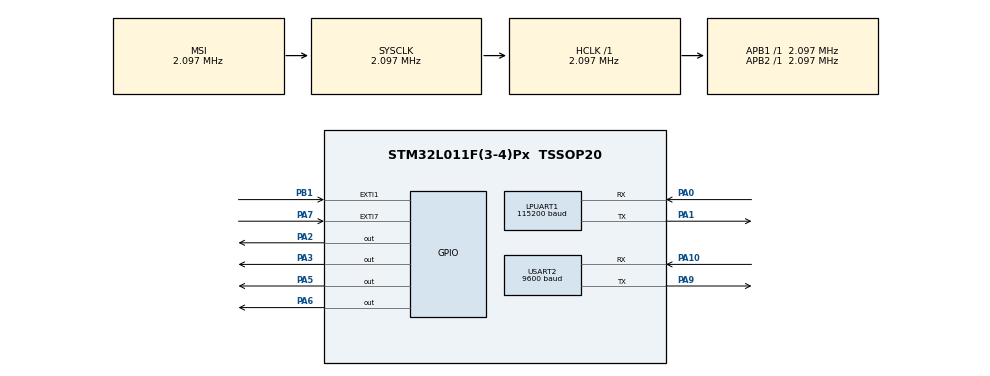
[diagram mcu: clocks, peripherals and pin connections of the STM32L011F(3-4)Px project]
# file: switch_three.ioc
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Dma.LPUART1_RX.0.Direction=DMA_PERIPH_TO_MEMORY
Dma.LPUART1_RX.0.Instance=DMA1_Channel3
Dma.LPUART1_RX.0.MemDataAlignment=DMA_MDATAALIGN_BYTE
Dma.LPUART1_RX.0.MemInc=DMA_MINC_ENABLE
Dma.LPUART1_RX.0.Mode=DMA_NORMAL
Dma.LPUART1_RX.0.PeriphDataAlignment=DMA_PDATAALIGN_BYTE
Dma.LPUART1_RX.0.PeriphInc=DMA_PINC_DISABLE
Dma.LPUART1_RX.0.Priority=DMA_PRIORITY_LOW
Dma.Request0=LPUART1_RX
Dma.Request1=USART2_RX
Dma.USART2_RX.1.Direction=DMA_PERIPH_TO_MEMORY
Dma.USART2_RX.1.Instance=DMA1_Channel5
Dma.USART2_RX.1.MemDataAlignment=DMA_MDATAALIGN_BYTE
Dma.USART2_RX.1.MemInc=DMA_MINC_ENABLE
Dma.USART2_RX.1.Mode=DMA_NORMAL
Dma.USART2_RX.1.PeriphDataAlignment=DMA_PDATAALIGN_BYTE
Dma.USART2_RX.1.PeriphInc=DMA_PINC_DISABLE
Dma.USART2_RX.1.Priority=DMA_PRIORITY_LOW
LPUART1.BaudRate=115200
LPUART1.MSBFirstParam=UART_ADVFEATURE_MSBFIRST_ENABLE
Mcu.Family=STM32L0
Mcu.Name=STM32L011F(3-4)Px
Mcu.Package=TSSOP20
NVIC.AES_RNG_LPUART1_IRQn=true\:0\:0\:false\:false\:true\:true
NVIC.DMA1_Channel2_3_IRQn=true\:0\:0\:false\:false\:true\:false
NVIC.DMA1_Channel4_5_6_7_IRQn=true\:0\:0\:false\:false\:true\:false
NVIC.EXTI0_1_IRQn=true\:0\:0\:false\:false\:true\:true
NVIC.EXTI4_15_IRQn=true\:0\:0\:false\:false\:true\:true
NVIC.USART2_IRQn=true\:0\:0\:false\:false\:true\:true
PA0-CK_IN.Mode=Asynchronous
PA0-CK_IN.Signal=LPUART1_RX
PA1.Mode=Asynchronous
PA1.Signal=LPUART1_TX
PA10.Mode=Asynchronous
PA10.Signal=USART2_RX
PA13.Mode=Serial_Wire
PA13.Signal=SYS_SWDIO
PA14.Mode=Serial_Wire
PA14.Signal=SYS_SWCLK
PA2.Signal=GPIO_Output
PA3.Signal=GPIO_Output
PA5.Signal=GPIO_Output
PA6.Signal=GPIO_Output
PA7.Signal=GPXTI7
PA9.Mode=Asynchronous
PA9.Signal=USART2_TX
PB1.Signal=GPXTI1
PC14-OSC32_IN.Mode=LSE-External-Oscillator
PC14-OSC32_IN.Signal=RCC_OSC32_IN
PC15-OSC32_OUT.Mode=LSE-External-Oscillator
PC15-OSC32_OUT.Signal=RCC_OSC32_OUT
ProjectManager.HeapSize=0x200
ProjectManager.StackSize=0x400
ProjectManager.TargetToolchain=MDK-ARM V5
RCC.AHBFreq_Value=2097000
RCC.APB1Freq_Value=2097000
RCC.APB1TimFreq_Value=2097000
RCC.APB2Freq_Value=2097000
RCC.APB2TimFreq_Value=2097000
RCC.HSE_VALUE=8000000
RCC.HSI16_VALUE=16000000
RCC.HSI_VALUE=16000000
RCC.MSI_VALUE=2097000
RCC.SYSCLKFreq_VALUE=2097000
RCC.VCOOutputFreq_Value=48000000
USART2.BaudRate=9600
USART2.MSBFirstParam=ADVFEATURE_MSBFIRST_ENABLE
USART2.VirtualMode-Asynchronous=VM_ASYNC
board=custom

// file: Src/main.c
#include "includes.h"

UART_HandleTypeDef hlpuart1;
UART_HandleTypeDef huart2;
DMA_HandleTypeDef hdma_lpuart1_rx;
DMA_HandleTypeDef hdma_lpuart1_tx;
DMA_HandleTypeDef hdma_usart2_rx;
DMA_HandleTypeDef hdma_usart2_tx;

/* USER CODE BEGIN PV */
/* Private variables ---------------------------------------------------------*/

/* USER CODE END PV */

/* Size of Trasmission buffer */
#define TXBUFFERSIZE                      (COUNTOF(aTxBuffer) - 1)
/* Size of Reception buffer */
#define RXBUFFERSIZE                      TXBUFFERSIZE
#define COUNTOF(__BUFFER__)   (sizeof(__BUFFER__) / sizeof(*(__BUFFER__)))

/* uart2 receive  parameter*/
uint8_t rx_buffer[100] = {0};
uint8_t tx_buffer[100] = {0};
uint16_t rx_len = 0;
/* UART handler declaration */
__IO ITStatus UartReady = RESET;

uint8_t aTxBuffer[] = " ****UART_TwoBoards_ComIT****  ****UART_TwoBoards_ComIT****  ****UART_TwoBoards_ComIT**** ";

/* Buffer used for reception */
uint8_t aRxBuffer[RXBUFFERSIZE];

/* is done recevice */
uint8_t recv_end_flag = 0;

int main(void)
{
	/* Reset of all peripherals, Initializes the Flash interface and the Systick. */
	HAL_Init();

	/* Configure the system clock */
	SystemClock_Config();

	/* Initialize all configured peripherals */
	MX_GPIO_Init();
	//MX_DMA_Init();
	MX_LPUART1_UART_Init();
	MX_USART2_UART_Init();

	while (1)
	{
//wifi串口数据解析
//继电器控制
//485数据解析
	//	HAL_UART_Transmit_DMA(&huart2, "test", 5); //
	//	rx_len = 0;
	//	recv_end_flag = 0;
	//	HAL_UART_Receive_DMA(&huart2, rx_buffer, BUFFER_SIZE);
		//灯
		 HAL_GPIO_TogglePin(GPIOA, GPIO_PIN_4);
		//继电器控制
		HAL_GPIO_TogglePin(GPIOA, GPIO_PIN_3);
    /* Insert delay 100 ms */
    HAL_Delay(3000);

	}

}

void SystemClock_Config(void)
{

	RCC_OscInitTypeDef RCC_OscInitStruct={0};
	RCC_ClkInitTypeDef RCC_ClkInitStruct={0};

	/**Configure the main internal regulator output voltage
	*/
	__HAL_PWR_VOLTAGESCALING_CONFIG(PWR_REGULATOR_VOLTAGE_SCALE1);

	/**Initializes the CPU, AHB and APB busses clocks
	*/
	RCC_OscInitStruct.OscillatorType = RCC_OSCILLATORTYPE_MSI;
	RCC_OscInitStruct.MSIState = RCC_MSI_ON;
	RCC_OscInitStruct.MSICalibrationValue = 0;
	RCC_OscInitStruct.MSIClockRange = RCC_MSIRANGE_5;
	RCC_OscInitStruct.PLL.PLLState = RCC_PLL_NONE;

	if (HAL_RCC_OscConfig(&RCC_OscInitStruct) != HAL_OK)
	{
		_Error_Handler(__FILE__, __LINE__);
	}

	/**Initializes the CPU, AHB and APB busses clocks
	*/
	RCC_ClkInitStruct.ClockType = RCC_CLOCKTYPE_HCLK | RCC_CLOCKTYPE_SYSCLK
								  | RCC_CLOCKTYPE_PCLK1 | RCC_CLOCKTYPE_PCLK2;
	RCC_ClkInitStruct.SYSCLKSource = RCC_SYSCLKSOURCE_MSI;
	RCC_ClkInitStruct.AHBCLKDivider = RCC_SYSCLK_DIV1;
	RCC_ClkInitStruct.APB1CLKDivider = RCC_HCLK_DIV1;
	RCC_ClkInitStruct.APB2CLKDivider = RCC_HCLK_DIV1;

	if (HAL_RCC_ClockConfig(&RCC_ClkInitStruct, FLASH_LATENCY_0) != HAL_OK)
	{
		_Error_Handler(__FILE__, __LINE__);
	}

	/**Configure the Systick interrupt time
	*/
	HAL_SYSTICK_Config(HAL_RCC_GetHCLKFreq() / 1000);

	/**Configure the Systick
	*/
	HAL_SYSTICK_CLKSourceConfig(SYSTICK_CLKSOURCE_HCLK);

	/* SysTick_IRQn interrupt configuration */
	HAL_NVIC_SetPriority(SysTick_IRQn, 0, 0);

}

/* LPUART1 init function */
void MX_LPUART1_UART_Init(void)
{

	hlpuart1.Instance = LPUART1;
	hlpuart1.Init.BaudRate = 115200;
	hlpuart1.Init.WordLength = UART_WORDLENGTH_8B;
	hlpuart1.Init.StopBits = UART_STOPBITS_1;
	hlpuart1.Init.Parity = UART_PARITY_NONE;
	hlpuart1.Init.Mode = UART_MODE_TX_RX;
	hlpuart1.Init.HwFlowCtl = UART_HWCONTROL_NONE;
	//hlpuart1.Init.OneBitSampling = UART_ONE_BIT_SAMPLE_DISABLE;
	//hlpuart1.AdvancedInit.AdvFeatureInit = UART_ADVFEATURE_MSBFIRST_INIT;
	//hlpuart1.AdvancedInit.MSBFirst = UART_ADVFEATURE_MSBFIRST_ENABLE;
  if(HAL_UART_DeInit(&hlpuart1) != HAL_OK)
  {
    Error_Handler();
  }
	if (HAL_UART_Init(&hlpuart1) != HAL_OK)
	{
		_Error_Handler(__FILE__, __LINE__);
	}

	//DMA处理收发开始---

  /*##-2- Program the Reception process #####################################*/
  if(HAL_UART_Receive_DMA(&hlpuart1, (uint8_t *)aRxBuffer, RXBUFFERSIZE) != HAL_OK)
  {
    Error_Handler();
  }

  /*##-3- Start the transmission process #####################################*/
  /* While the UART in reception process, user can transmit data through
     "aTxBuffer" buffer */
  if(HAL_UART_Transmit_DMA(&hlpuart1, (uint8_t*)aTxBuffer, TXBUFFERSIZE)!= HAL_OK)
  {
    Error_Handler();
  }

  /*##-4- Wait for the end of the transfer ###################################*/
  while (UartReady != SET)
  {
  }

  /* Reset transmission flag */
  UartReady = RESET;

	//DMA处理收发结束---

	//以下是中断实现串口收发
	/*
	//串口中断实现接收和发送***开始***
	if(HAL_UART_Transmit_IT(&hlpuart1, (uint8_t*)aTxBuffer, TXBUFFERSIZE)!= HAL_OK)
  {
    Error_Handler();
  }

  // 等待发送完成###################################
  while (UartReady != SET)
  {
		 HAL_GPIO_TogglePin(GPIOA, GPIO_PIN_4);
		 HAL_Delay(3000);
  }
	   //复位处理标识
  UartReady = RESET;
	  //设置接收中断 ###########################
  if(HAL_UART_Receive_IT(&hlpuart1, (uint8_t *)aRxBuffer, RXBUFFERSIZE) != HAL_OK)
  {
    Error_Handler();
  }

  //等待接收

  while (UartReady != SET)
  {
		HAL_GPIO_TogglePin(GPIOA, GPIO_PIN_4);
      HAL_Delay(3000);
  }

	//串口中断实现接收和发送---结束---
  */

}

/* USART2 init function */
void MX_USART2_UART_Init(void)
{
	huart2.Instance = USART2;
	huart2.Init.BaudRate = 115200;
	huart2.Init.WordLength = UART_WORDLENGTH_8B;
	huart2.Init.StopBits = UART_STOPBITS_1;
	huart2.Init.Parity = UART_PARITY_NONE;
	huart2.Init.Mode = UART_MODE_TX_RX;
	huart2.Init.HwFlowCtl = UART_HWCONTROL_NONE;
	huart2.Init.OverSampling = UART_OVERSAMPLING_16;
	huart2.Init.OneBitSampling = UART_ONE_BIT_SAMPLE_DISABLE;
	huart2.AdvancedInit.AdvFeatureInit = UART_ADVFEATURE_NO_INIT;

	if (HAL_UART_Init(&huart2) != HAL_OK)
	{
		_Error_Handler(__FILE__, __LINE__);
	}

	//?D??'?a
	__HAL_UART_ENABLE_IT(&huart2, UART_IT_IDLE);
	HAL_UART_Receive_DMA(&huart2, rx_buffer, BUFFER_SIZE);
	HAL_UART_Transmit_DMA(&huart2, tx_buffer, BUFFER_SIZE);

}

void MX_DMA_Init(void)
{
	/* DMA controller clock enable */
	__HAL_RCC_DMA1_CLK_ENABLE();

	/* DMA interrupt init */
	/* DMA1_Channel2_3_IRQn interrupt configuration */
	HAL_NVIC_SetPriority(DMA1_Channel2_3_IRQn, 0, 0);
	HAL_NVIC_EnableIRQ(DMA1_Channel2_3_IRQn);

}

/** Configure pins as
        * Analog
        * Input
        * Output
        * EVENT_OUT
        * EXTI
*/
void MX_GPIO_Init(void)
{

	GPIO_InitTypeDef GPIO_InitStruct;

	/* GPIO Ports Clock Enable */
	__HAL_RCC_GPIOC_CLK_ENABLE();
	__HAL_RCC_GPIOA_CLK_ENABLE();
	__HAL_RCC_GPIOB_CLK_ENABLE();

	/*Configure GPIO pin Output Level */
	HAL_GPIO_WritePin(GPIOA, GPIO_PIN_2 | GPIO_PIN_3 | GPIO_PIN_5 | GPIO_PIN_6, GPIO_PIN_RESET);

	/*Configure GPIO pins : PA2 PA3 PA5 PA6 */
	GPIO_InitStruct.Pin = GPIO_PIN_2 | GPIO_PIN_3 | GPIO_PIN_5 | GPIO_PIN_6 | GPIO_PIN_4;
	GPIO_InitStruct.Mode = GPIO_MODE_OUTPUT_PP;
	GPIO_InitStruct.Pull = GPIO_NOPULL;
	GPIO_InitStruct.Speed = GPIO_SPEED_FREQ_LOW;
	HAL_GPIO_Init(GPIOA, &GPIO_InitStruct);

	/*Configure GPIO pin : PA7 */
	GPIO_InitStruct.Pin = GPIO_PIN_7;
	GPIO_InitStruct.Mode = GPIO_MODE_IT_RISING;
	GPIO_InitStruct.Pull = GPIO_NOPULL;
	HAL_GPIO_Init(GPIOA, &GPIO_InitStruct);

	/*Configure GPIO pin : PB1 */
	GPIO_InitStruct.Pin = GPIO_PIN_1;
	GPIO_InitStruct.Mode = GPIO_MODE_IT_RISING;
	GPIO_InitStruct.Pull = GPIO_NOPULL;
	HAL_GPIO_Init(GPIOB, &GPIO_InitStruct);

	/* EXTI interrupt init*/
	HAL_NVIC_SetPriority(EXTI0_1_IRQn, 0, 0);
	HAL_NVIC_EnableIRQ(EXTI0_1_IRQn);

	HAL_NVIC_SetPriority(EXTI4_15_IRQn, 0, 0);
	HAL_NVIC_EnableIRQ(EXTI4_15_IRQn);

}

/* USER CODE BEGIN 4 */
void HAL_UART_RxCpltCallback(UART_HandleTypeDef *huart)
{
	/* Set transmission flag: transfer complete */
  UartReady = SET;

	/* NOTE : This function should not be modified, when the callback is needed,
	          the HAL_UART_RxCpltCallback can be implemented in the user file.
	 */
}
void HAL_UART_TxCpltCallback(UART_HandleTypeDef *UartHandle)
{
  /* Set transmission flag: transfer complete */
  UartReady = SET;

}

/* USER CODE END 4 */

void _Error_Handler(char *file, int line)
{
	while(1)
	{
	}
}

/************************ (C) COPYRIGHT STMicroelectronics *****END OF FILE****/
